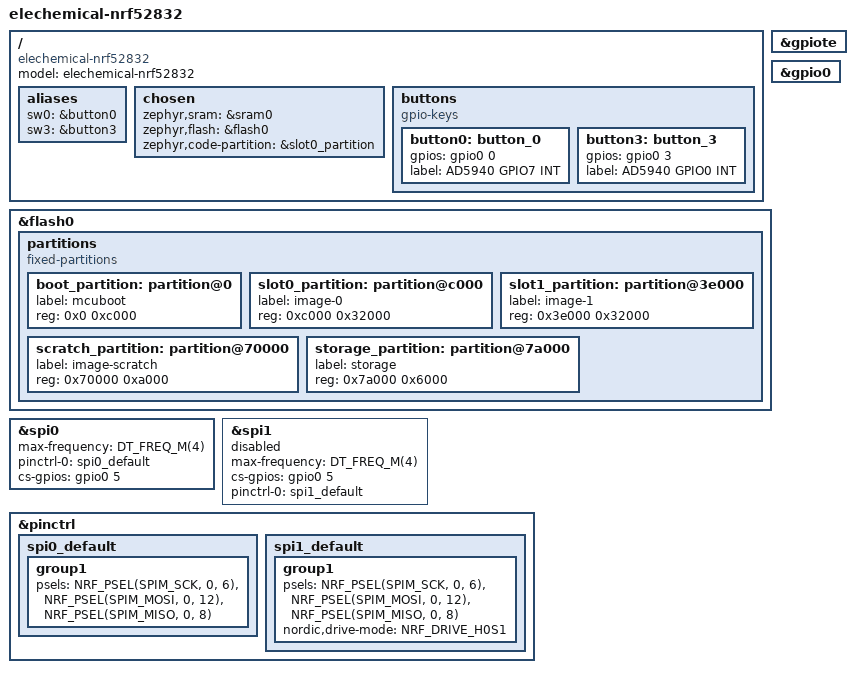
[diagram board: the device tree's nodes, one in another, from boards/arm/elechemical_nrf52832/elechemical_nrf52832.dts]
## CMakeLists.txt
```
cmake_minimum_required(VERSION 3.20.0)
find_package(Zephyr REQUIRED HINTS $ENV{ZEPHYR_BASE})

project(ElectrochemicalWorkstationNRF52832)

FILE(GLOB app_sources src/*.c include/*.h drivers/*.c drivers/*.h elec_methods/*.h elec_methods/*.c)
target_sources(app PRIVATE ${app_sources} src/main.c)
```

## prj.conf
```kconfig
CONFIG_NRFX_GPIOTE=y
CONFIG_LOG=y
CONFIG_LOG_PROCESS_THREAD_SLEEP_MS=100

# Enable RTT to replace UART
CONFIG_STDOUT_CONSOLE=y
CONFIG_UART_CONSOLE=n
CONFIG_USE_SEGGER_RTT=y
CONFIG_SHELL_BACKEND_RTT=y

# enable internal 32k rc; if u need use external XTAL, set XTAL=y, rest would be '=n' automatically.
CONFIG_CLOCK_CONTROL_NRF_K32SRC_RC=y
CONFIG_CLOCK_CONTROL_NRF_K32SRC_XTAL=n

CONFIG_NEWLIB_LIBC=y
# CONFIG_NEWLIB_LIBC_FLOAT_PRINTF=y
CONFIG_CBPRINTF_FP_SUPPORT=y

# SPIM
CONFIG_GPIO=y
CONFIG_PINCTRL=y
CONFIG_SPI=y
CONFIG_NRFX_SPI0=y

CONFIG_BT=y
CONFIG_BT_DEBUG_LOG=y
CONFIG_BT_DEVICE_NAME="ElectrochemicalWorkstation"
CONFIG_BT_PERIPHERAL=y
CONFIG_BT_BAS=y
CONFIG_BT_USER_PHY_UPDATE=y
CONFIG_BT_BUF_ACL_RX_SIZE=500
CONFIG_BT_CTLR_PHY_2M=y
#GATT_CLIENT needed for requesting ATT_MTU update
CONFIG_BT_GATT_CLIENT=y
#PHY update needed for updating PHY request
CONFIG_BT_USER_PHY_UPDATE=y
#For data length update
CONFIG_BT_USER_DATA_LEN_UPDATE=y
#This is the maximum data length with Nordic Softdevice controller
CONFIG_BT_CTLR_DATA_LENGTH_MAX=251
#These buffers are needed for the data length max. 
CONFIG_BT_BUF_ACL_TX_SIZE=500
CONFIG_BT_BUF_ACL_RX_SIZE=500
#This is the maximum MTU size with Nordic Softdevice controller
CONFIG_BT_L2CAP_TX_MTU=500

# DIS Service
CONFIG_BT_DIS=y
CONFIG_BT_DIS_PNP=n
CONFIG_BT_DIS_MODEL="ElecWs"
CONFIG_BT_DIS_MANUF="RoumaiMed"
CONFIG_BT_DIS_SERIAL_NUMBER=y
CONFIG_BT_DIS_FW_REV=y
CONFIG_BT_DIS_HW_REV=y
CONFIG_BT_DIS_SW_REV=y
CONFIG_BT_DIS_SERIAL_NUMBER_STR="F.A000001"
CONFIG_BT_DIS_FW_REV_STR="Roumai Firmware"
CONFIG_BT_DIS_HW_REV_STR="Roumai Hardware"
CONFIG_BT_DIS_SW_REV_STR="Roumai Software"
# Below is setup to let DIS information be read from settings
CONFIG_BT_SETTINGS=y
CONFIG_SETTINGS=y
CONFIG_SETTINGS_NONE=y

CONFIG_BT_DIS_SETTINGS=y
CONFIG_BT_DIS_STR_MAX=21
```

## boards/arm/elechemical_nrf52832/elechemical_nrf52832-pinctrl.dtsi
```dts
/*
 * Copyright (c) 2022 Nordic Semiconductor
 * SPDX-License-Identifier: Apache-2.0
 */

 &pinctrl {

	spi0_default: spi0_default {
		group1 {
      psels = <NRF_PSEL(SPIM_SCK, 0, 6)>,
              <NRF_PSEL(SPIM_MOSI, 0, 12)>,
              <NRF_PSEL(SPIM_MISO, 0, 8)>;
		};
	};

	spi0_sleep: spi0_sleep {
		group1 {
      psels = <NRF_PSEL(SPIM_SCK, 0, 6)>,
              <NRF_PSEL(SPIM_MOSI, 0, 12)>,
              <NRF_PSEL(SPIM_MISO, 0, 8)>;
			low-power-enable;
		};
	};

};
```

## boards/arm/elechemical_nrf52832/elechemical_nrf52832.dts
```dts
// Copyright (c) 2023 Nordic Semiconductor ASA
// SPDX-License-Identifier: Apache-2.0

/dts-v1/;
#include <nordic/nrf52832_ciaa.dtsi>
// #include "elechemical-nrf52832-pinctrl.dtsi"

/ {
	model = "elechemical-nrf52832";
	compatible = "elechemical-nrf52832";
  
  aliases {
    sw0 = &button0;
    sw3 = &button3;
  };
	
  chosen {
		zephyr,sram = &sram0;
		zephyr,flash = &flash0;
		zephyr,code-partition = &slot0_partition;
	};

  buttons {
    compatible = "gpio-keys";
    button0: button_0 {
			gpios = <&gpio0 0 (GPIO_PULL_UP | GPIO_ACTIVE_HIGH)>;
      label = "AD5940 GPIO7 INT";
    };
    button3: button_3 {
			gpios = <&gpio0 3 (GPIO_PULL_UP | GPIO_ACTIVE_HIGH)>;
      label = "AD5940 GPIO0 INT";
    };
    /* ... other buttons ... */
  };
  
};

// &uart0 {
// 	compatible = "nordic,nrf-uarte";
// 	status = "okay";
// 	current-speed = <115200>;
// 	pinctrl-0 = <&uart0_default>;
// 	pinctrl-1 = <&uart0_sleep>;
// 	pinctrl-names = "default", "sleep";
// };

&gpiote {
	status = "okay";
};

&gpio0 {
	status = "okay";
};

&flash0 {
	partitions {
		compatible = "fixed-partitions";
		#address-cells = <1>;
		#size-cells = <1>;

		boot_partition: partition@0 {
			label = "mcuboot";
			reg = <0x0 0xc000>;
		};
		slot0_partition: partition@c000 {
			label = "image-0";
			reg = <0xc000 0x32000>;
		};
		slot1_partition: partition@3e000 {
			label = "image-1";
			reg = <0x3e000 0x32000>;
		};
		scratch_partition: partition@70000 {
			label = "image-scratch";
			reg = <0x70000 0xa000>;
		};
		storage_partition: partition@7a000 {
			label = "storage";
			reg = <0x7a000 0x6000>;
		};
	};
};


&spi0 {
  status = "okay";
  max-frequency = <DT_FREQ_M(4)>;
  pinctrl-0 = <&spi0_default>;
  pinctrl-names = "default";
  cs-gpios = <&gpio0 5 0>;
};

&spi1 {
  status = "disabled";
  max-frequency = <DT_FREQ_M(4)>;
  cs-gpios = <&gpio0 5 0>;
  pinctrl-0 = <&spi1_default>;
  pinctrl-names = "default";
};

&pinctrl {
  spi0_default: spi0_default {
    group1 {
      psels = <NRF_PSEL(SPIM_SCK, 0, 6)>,
              <NRF_PSEL(SPIM_MOSI, 0, 12)>,
              <NRF_PSEL(SPIM_MISO, 0, 8)>;
    };
  };

  spi1_default: spi1_default {
    group1 {
      psels = <NRF_PSEL(SPIM_SCK, 0, 6)>,
              <NRF_PSEL(SPIM_MOSI, 0, 12)>,
              <NRF_PSEL(SPIM_MISO, 0, 8)>;
      nordic,drive-mode = <NRF_DRIVE_H0S1>;
    };
  };
};
```

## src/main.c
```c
#include <zephyr/kernel.h>
#include <zephyr/logging/log.h>
#include <zephyr/sys/util.h>
#include <zephyr/settings/settings.h>
#include <zephyr/bluetooth/bluetooth.h>
#include <zephyr/bluetooth/gatt.h>
#include <unistd.h> // For sleep function
#include <stdlib.h> // For EXIT_FAILURE and EXIT_SUCCESS

#include "../include/ble_protocal.h"
#include "../include/ble_faca.h"
#include "../drivers/ad5940_nrf52.h"
#include "../drivers/dac.h"// Include DAC driver header


LOG_MODULE_REGISTER(app, LOG_LEVEL_INF);

void mtu_updated(struct bt_conn *conn, uint16_t tx, uint16_t rx)
{
	printk("Updated MTU: TX: %d RX: %d bytes\n", tx, rx);
}

static struct bt_gatt_cb gatt_callbacks = {.att_mtu_updated = mtu_updated};

void main(void)
{
  int err = 0;
  // AD5940
  err = ad5940_spi_init();
  if (err)
  {
    LOG_ERR("AD5940 SPI init failed (err %d)", err);
    return;
  }

  err = ad5940_enable_int();
  if (err)
  {
    LOG_ERR("AD5940 INT init failed (err %d)", err);
    return;
  }
  LOG_INF("AD5940 init success.");

  // Bluetooth
  err = bt_enable(NULL);
  if (err)
  {
    LOG_ERR("Bluetooth init failed (err %d)", err);
    return;
  }
  bt_gatt_cb_register(&gatt_callbacks);
  LOG_INF("Bluetooth init success.");
  if (IS_ENABLED(CONFIG_BT_SETTINGS))
  {
    settings_load();
    LOG_INF("Settings init success.");
  }
  err = ble_init_adv();
  if (err)
  {
    LOG_ERR("Bluetooth adv init failed (err %d)", err);
    return;
  }
  LOG_INF("Bluetooth adv init success.");
  err = ble_start_adv();
  if (err)
  {
    LOG_ERR("Bluetooth adv start failed (err %d)", err);
    return;
  }
  LOG_INF("Bluetooth adv start success.");

  err = ble_faca_init();
  if (err)
  {
    LOG_ERR("Bluetooth faca init failed (err %d)", err);
    return;
  }
  LOG_INF("Bluetooth faca init success.");
  
  for(;;) {
    k_msleep(1);
  }
}

//adc
#define ADC_CHANNEL 1
void adc_task(void)
{
    if (adc_init() != 0) {
        printf("ADC初始化失败！\n");
        return;
    }
    printf("ADC初始化成功，开始读取数据...\n");

    // 循环读取ADC值
    while (1) {
        // 读取原始ADC值
        uint16_t adc_value = adc_read(ADC_CHANNEL);

        // 检查读取是否成功（假设返回0xFFFF表示失败）
        if (adc_value == 0xFFFF) {
            printf("读取ADC通道 %d 失败\n", ADC_CHANNEL);
        } else {
            // 转换为电压值
            float result = *adc_read(ADC_CHANNEL);

            // 打印结果
            printf("ADC通道 %d: 原始值 = %d, 电压 = %.2fV\n",
                   ADC_CHANNEL, adc_value, result);
        }

        // 每隔1秒读取一次
        sleep(1);
    }
    // 释放ADC资源（实际中可能不会执行到这里）
    adc_deinit();
}
```

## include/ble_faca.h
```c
#include <stdint.h>

#define BLE_CMD_BLUFI_SSIDPSWD    0x01
#define BLE_CMD_BLUFI_DISCONNECT  0x02
#define BLE_CMD_SESSION_START     0x03
#define BLE_CMD_SESSION_TS        0x04
#define BLE_CMD_SESSION_STOP      0x05
#define BLE_CMD_GET_WIFI_CONFIG   0x06
#define BLE_CMD_GET_TASK_CONFIG   0x07
#define BLE_CMD_POST_TASK_CONFIG  0x08
#define BLE_CMD_READ_REGISTER     0x09
#define BLE_CMD_WRITE_REGISTER    0x0A

int ble_faca_init();
```

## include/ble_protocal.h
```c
#include <stdint.h>

int ble_init_adv();

int ble_start_adv();

int ble_stop_adv();
```

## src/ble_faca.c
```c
#ifndef ENABLE_FACA_SERVICE__
#define ENABLE_FACA_SERVICE__

#include "../include/ble_faca.h"

#include <stdlib.h>

#include <zephyr/bluetooth/bluetooth.h>
#include <zephyr/bluetooth/hci.h>
#include <zephyr/bluetooth/conn.h>
#include <zephyr/bluetooth/uuid.h>
#include <zephyr/bluetooth/gatt.h>

#include <zephyr/logging/log.h>
LOG_MODULE_REGISTER(faca, LOG_LEVEL_INF);

// Electrochemical Methods
#include "../elec_methods/common.h"
#include "../elec_methods/ocp.h"
#include "../elec_methods/eis.h"
#include "../elec_methods/cv.h"
#include "../elec_methods/ca.h"


// Looper

#define LOOPER_INTERVAL         1     // 1ms

static void looper_work_handler(struct k_work *work);

static K_WORK_DELAYABLE_DEFINE(looper_work, looper_work_handler);

// Task
static volatile uint8_t current_elec_method = 0x00; // undefined.
static inline void reset_current_elec_method() { current_elec_method = 0x00; }

#define BLE_BUFFER_MAX_SIZE 20
static          uint8_t buffer_copi[BLE_BUFFER_MAX_SIZE];
static volatile uint8_t buffer_size = BLE_BUFFER_MAX_SIZE;
static volatile bool    buffer_done = false;

// Bluetooth

#define FACA_INDEX        0
#define FAC1_INDEX        2
#define FAC2_INDEX        4
#define FAC2_CCC_INDEX    5
#define FAC3_INDEX        7
#define FAC3_CCC_INDEX    8

static uint8_t response_values[500];
static volatile bool notify_fac2_enable;
static volatile bool notify_fac3_enable;
static void mpu_ccc_cfg_changed_fac2(const struct bt_gatt_attr *attr, uint16_t value)
{
	ARG_UNUSED(attr);
	notify_fac2_enable = (value == BT_GATT_CCC_NOTIFY);
	// LOG_INF("Notification %s", notify_enable ? "enabled" : "disabled");
}
static void mpu_ccc_cfg_changed_fac3(const struct bt_gatt_attr *attr, uint16_t value)
{
	ARG_UNUSED(attr);
	notify_fac3_enable = (value == BT_GATT_CCC_NOTIFY);
  // LOG_INF("notify_fac3_enable: %d", notify_fac3_enable ? 1 : 0);
}
static ssize_t read_faca(struct bt_conn *conn, const struct bt_gatt_attr *attr,
   void *buf, uint16_t len, uint16_t offset);
static ssize_t on_request_arrived(struct bt_conn *conn,
		    const struct bt_gatt_attr *attr, const void *buf,
		    uint16_t len, uint16_t offset, uint8_t flags);

static struct bt_uuid_128 faca_service_uuid = BT_UUID_INIT_128(
	BT_UUID_128_ENCODE(0x0000faca, 0x0000, 0x1000, 0x8000, 0x00805f9b34fb));

// FAC1: recv payload from master.
static struct bt_uuid_128 fac1_char_uuid = BT_UUID_INIT_128(
	BT_UUID_128_ENCODE(0x0000fac1, 0x0000, 0x1000, 0x8000, 0x00805f9b34fb));

// FAC2: notify normal callback.
static struct bt_uuid_128 fac2_char_uuid = BT_UUID_INIT_128(
	BT_UUID_128_ENCODE(0x0000fac2, 0x0000, 0x1000, 0x8000, 0x00805f9b34fb));

// FAC3: notify adc data. "0000fac3-0000-1000-8000-00805f9b34fb"
static struct bt_uuid_128 fac3_char_uuid = BT_UUID_INIT_128(
	BT_UUID_128_ENCODE(0x0000fac3, 0x0000, 0x1000, 0x8000, 0x00805f9b34fb));

BT_GATT_SERVICE_DEFINE(faca_service,
  BT_GATT_PRIMARY_SERVICE(&faca_service_uuid),
  BT_GATT_CHARACTERISTIC(&fac1_char_uuid.uuid,
            BT_GATT_CHRC_WRITE | BT_GATT_CHRC_WRITE_WITHOUT_RESP,
            BT_GATT_PERM_WRITE, NULL, on_request_arrived, (void *)1),
  BT_GATT_CHARACTERISTIC(&fac2_char_uuid.uuid, BT_GATT_CHRC_NOTIFY | BT_GATT_CHRC_READ,
            BT_GATT_PERM_READ | BT_GATT_PERM_WRITE, read_faca, NULL, &response_values),
  // BT_GATT_CUD("Fade2 CUD", BT_GATT_PERM_READ),
  BT_GATT_CCC(mpu_ccc_cfg_changed_fac2, BT_GATT_PERM_READ | BT_GATT_PERM_WRITE),
  BT_GATT_CHARACTERISTIC(&fac3_char_uuid.uuid, BT_GATT_CHRC_NOTIFY | BT_GATT_CHRC_READ,
            BT_GATT_PERM_READ | BT_GATT_PERM_WRITE, read_faca, NULL, &buffer_copi),
  // BT_GATT_CUD("Fade3 CUD", BT_GATT_PERM_READ),
  BT_GATT_CCC(mpu_ccc_cfg_changed_fac3, BT_GATT_PERM_READ | BT_GATT_PERM_WRITE),
);

static ssize_t read_faca(struct bt_conn *conn, const struct bt_gatt_attr *attr,
   void *buf, uint16_t len, uint16_t offset)
{
  const char *value = attr->user_data;
  return bt_gatt_attr_read(conn, attr, buf, len, offset, value, strlen(value));
}

///////////////////////////////////////////// FAC2 Reply //////////////////////////////////////////////////

// static void reply_response_with_data(uint16_t request_id, uint8_t status, uint8_t * data, uint8_t len)
// {
//   response_values[0] = (uint8_t)(request_id >> 8) & 0xFF;
//   response_values[1] = (request_id & 0xFF);
//   response_values[2] = status;
//   for (uint8_t i = 0; i < len; i++) {
//     response_values[i + 3] = data[i];
//   }
//   uint8_t err = bt_gatt_notify(NULL, &faca_service.attrs[FAC2_INDEX], &response_values, len + 3);
//   if (err) {
//     // ...
//     // LOG_ERR("faca2 reply json error, err = %02x", err);
//   }
// }
static void reply_response(uint16_t request_id, uint8_t status)
{
  response_values[0] = (uint8_t)((request_id >> 8) & 0xFF);
  response_values[1] = (request_id & 0xFF);
  response_values[2] = status;
  uint8_t err = bt_gatt_notify(NULL, &faca_service.attrs[FAC2_INDEX], &response_values, 3);
  if (err) {
    // ...
    // LOG_ERR("faca2 reply json error, err = %02x", err);
  }
}

///////////////////////////////////////////// FAC3 Notify //////////////////////////////////////////////////

// worker, implement from common.h
void send_fac_stream(uint8_t * data, uint8_t len)
{
  buffer_copi[0] = current_elec_method;
  // copy buffer
  for (uint8_t i = 0; i < len; i++) {
    buffer_copi[i + 1] = data[i];
  }
  buffer_size = len + 1;
  // signal flag
  buffer_done = true;
}

int send_fac_stream_directly(uint8_t * data, uint8_t len)
{
  uint8_t buffer_[len];
  buffer_[0] = current_elec_method;
  for (int i = 0; i < len; i++) {
    buffer_[i + 1] = data[i];
  }
  int err = bt_gatt_notify(NULL, &faca_service.attrs[FAC3_INDEX], &buffer_, (len + 1));
  if (err) {
    return err;
  }
  return 0;
}


#define COMMIT_BUFFER_MAX_LEN 4096
#define COMMIT_BUFFER_EACH_LEN 20
static volatile uint32_t c_buffer_size;
static volatile uint32_t c_buffer_index; // for sender process.
static uint8_t c_buffer[COMMIT_BUFFER_MAX_LEN];
void commit_fac_stream(uint8_t * data, uint8_t len, bool append)
{
  // buffer here.
  int index = 0;
  if (append) {
    index = c_buffer_size;
  } else {
    index = 0;
    c_buffer_index = 0;
  }
  for(int i = 0; i < len; i++) {
    c_buffer[index++] = data[i];
  }
  c_buffer_size = index;
}


static inline void stop_other_elec_methods(uint8_t except_code) {
  if (except_code != CODE_OCP) {
    if (elec_ocp_is_working()) elec_ocp_stop();
  }
  if (except_code != CODE_EIS) {
    if (elec_eis_is_working()) elec_eis_stop();
  }
  if (except_code != CODE_CV) {
    if (elec_cv_is_working()) elec_cv_stop();
  }
  k_msleep(500); // 延迟 500ms 确保 AD5940 能正确重置
  // reset ad5940
  // ...
}


static ssize_t on_request_arrived(struct bt_conn *conn,
		    const struct bt_gatt_attr *attr, const void *buf,
		    uint16_t len, uint16_t offset, uint8_t flags)
{
  // parse json.
  LOG_INF("payload len: %d", len);
  if (len == 1) { // debug mode
    int err = 0; // ad594x_verify();
    LOG_INF("faca: ad594x debug verify: %02x", err);
    return 0;
  }
  /**
   * 
   * Request Payload Parser & Resp.
   * 
  */
  uint8_t * data = (uint8_t *)buf;
  uint16_t request_id = (uint16_t)(data[0] << 8) | (data[1] & 0xFF);
  uint8_t method = data[2] & 0xFF;
  switch(method) {
  case 0x01: // 计时电流法
  {
    break;
  }
  case CODE_OCP: // OCP
  {
    uint8_t code = data[3];
    if (code == 0x01) { // start cmd
      LOG_INF("Router: OCP/start");
      if (elec_ocp_is_working()) {
        reply_response(request_id, 1);
      } else {
        stop_other_elec_methods(method);
        elec_ocp_init();
        reply_response(request_id, 0);
        current_elec_method = method;
        // start work
        elec_ocp_start();
        // elec_ocp_start(&send_fac_stream);
      }
      break;
    }
    if (code == 0x02) { // stop cmd
      LOG_INF("Router: OCP/stop");
      elec_ocp_stop();
      reply_response(request_id, 0);
      reset_current_elec_method(); // reset
      break;
    }
    if (code == 0x03) { // config
      LOG_INF("Router: OCP/config");
      opc_config_t config;
      config.sample_frequency = data[4]; // positive integer, range in 1..50
      if (len >= 7) {
        config.delay = (data[5] << 8) | data[6];
      }
      elec_ocp_config(config);
      reply_response(request_id, 0);
      break;
    }
    break;
  }
  case CODE_EIS: // EIS
  {
    uint8_t code = data[3];
    if (code == 0x01) { // start cmd
      LOG_INF("Router: EIS/start");
      if (elec_eis_is_working()) {
        reply_response(request_id, 1);
      } else {
        stop_other_elec_methods(method);
        reply_response(request_id, 0);
        LOG_INF("EIS init#begin");
        elec_eis_init(); // will take a lot of time.
        current_elec_method = method;
        // start work
        LOG_INF("EIS start#begin");
        elec_eis_start();
        LOG_INF("EIS start#end");
      }
      break;
    }
    if (code == 0x02) { // stop cmd
      LOG_INF("Router: EIS/stop");
      elec_eis_stop();
      reply_response(request_id, 0);
      reset_current_elec_method(); // reset
      break;
    }
    if (code == 0x03) { // config cmd
      LOG_INF("Router: EIS/config");
      if (len < 19) {
        reply_response(request_id, 1);
        break;
      }
      uint32_t freq_begin = ((uint32_t)data[4]) << 24;
      freq_begin |= ((uint32_t)data[5]) << 16;
      freq_begin |= ((uint32_t)data[6]) << 8;
      freq_begin |= data[7] & 0xFF;

      uint32_t freq_end = ((uint32_t)data[8]) << 24;
      freq_end |= ((uint32_t)data[9]) << 16;
      freq_end |= ((uint32_t)data[10]) << 8;
      freq_end |= data[11] & 0xFF;

      uint16_t sample_count = ((uint32_t)data[12]) << 8;
      sample_count |= data[13] & 0xFF;

      bool use_log = data[14] > 0;

      int16_t ac_volt = ((uint32_t)data[15]) << 24;
      ac_volt |= ((uint32_t)data[16]) << 16;
      ac_volt |= ((uint32_t)data[17]) << 8;
      ac_volt |= data[18] & 0xFF;

      elec_eis_config_t config;
      config.freq_begin = freq_begin / 100.0F;
      config.freq_end   = freq_end / 100.0F;
      config.sample_count = sample_count;
      config.use_log    = use_log;
      config.ac_volt    = ac_volt / 100.0F;

      LOG_INF("=======eis config updated========");
      LOG_INF("freq begin:    %f Hz", config.freq_begin);
      LOG_INF("freq end:      %f Hz", config.freq_end);
      LOG_INF("sample count:  %d", config.sample_count);
      LOG_INF("use_log:       %s", config.use_log ? "yes" : "no");
      LOG_INF("ac volt:       %f mV", config.ac_volt);
      LOG_INF("=======eis config updated========");

      elec_eis_config(config);
      reply_response(request_id, 0);
      break;
    }
    break;
  }
  case CODE_CV: // CV
  {
    uint8_t code = data[3];
    if (code == 0x01) { // start cmd
      LOG_INF("Router: CV/start");
      if (elec_cv_is_working()) {
        reply_response(request_id, 1);
      } else {
        stop_other_elec_methods(method);
        elec_cv_init();
        reply_response(request_id, 0);
        current_elec_method = method;
        // start work
        elec_cv_start();
      }
      break;
    }
    if (code == 0x02) { // stop cmd
      LOG_INF("Router: CV/stop");
      elec_cv_stop();
      reply_response(request_id, 0);
      reset_current_elec_method(); // reset
      break;
    }
    if (code == 0x03) { // config cmd
      LOG_INF("Router: CV/config");
      if (len < 26) { // valid len: 6*int + 1*short = 26
        reply_response(request_id, 1);
        break;
      }
      int k = 4;
      elec_cv_config_t config;

      uint8_t rtia = data[k++];
      if (rtia > 0 && rtia <= 26) {
        config.rtia = rtia;
      }

      int32_t vertex_begin = ((uint32_t)data[k++]) << 24;
      vertex_begin |= ((uint32_t)data[k++]) << 16;
      vertex_begin |= ((uint32_t)data[k++]) << 8;
      vertex_begin |= data[k++] & 0xFF;
      config.vertex_begin = vertex_begin / 100.0f; // mV

      int32_t vertex_1 = ((uint32_t)data[k++]) << 24;
      vertex_1 |= ((uint32_t)data[k++]) << 16;
      vertex_1 |= ((uint32_t)data[k++]) << 8;
      vertex_1 |= data[k++] & 0xFF;
      config.vertex_1 = vertex_1 / 100.0f; // mV

      int32_t vertex_2 = ((uint32_t)data[k++]) << 24;
      vertex_2 |= ((uint32_t)data[k++]) << 16;
      vertex_2 |= ((uint32_t)data[k++]) << 8;
      vertex_2 |= data[k++] & 0xFF;
      config.vertex_2 = vertex_2 / 100.0f; // mV

      int32_t sample_delay = ((uint32_t)data[k++]) << 24;
      sample_delay |= ((uint32_t)data[k++]) << 16;
      sample_delay |= ((uint32_t)data[k++]) << 8;
      sample_delay |= data[k++] & 0xFF;
      config.sample_delay = sample_delay / 100.0f; // ms

      int32_t scan_rate = ((uint32_t)data[k++]) << 24;
      scan_rate |= ((uint32_t)data[k++]) << 16;
      scan_rate |= ((uint32_t)data[k++]) << 8;
      scan_rate |= data[k++] & 0xFF;
      config.scan_rate = scan_rate / 100.0f; // mV/s

      int32_t step_value = ((uint32_t)data[k++]) << 24;
      step_value |= ((uint32_t)data[k++]) << 16;
      step_value |= ((uint32_t)data[k++]) << 8;
      step_value |= data[k++] & 0xFF;
      config.step_value = step_value / 100.0f; // mV

      uint16_t cycle_number = ((uint16_t)data[k++]) << 8;
      cycle_number |= data[k++] & 0xFF;
      config.cycle_number = cycle_number;

      LOG_INF("=======cv config updated========");
      LOG_INF("begin volt:       %f mV", config.vertex_begin);
      LOG_INF("vertex1 volt:     %f mV", config.vertex_1);
      LOG_INF("vertex2 start:    %f mV", config.vertex_2);
      LOG_INF("step:             %f mV", config.step_value);
      LOG_INF("scan rate:        %f mV/s", config.scan_rate);
      LOG_INF("sample delay:     %f ms", config.sample_delay);
      LOG_INF("cycle number:     %d",    config.cycle_number);
      LOG_INF("r tia:            %d",    config.rtia);
      LOG_INF("=======cv config updated========");
      elec_cv_config(config);

      reply_response(request_id, 0);
      break;
    }
    break;
  }
  case CODE_CA: // CA
  {
    uint8_t code = data[3];
    if (code == 0x01) { // start cmd
      LOG_INF("Router: CA/start");
      if (elec_ca_is_working()) {
        reply_response(request_id, 1);
      } else {
        stop_other_elec_methods(method);
        elec_ca_init();
        reply_response(request_id, 0);
        current_elec_method = method;
        // start work
        elec_ca_start();
      }
      break;
    }
    if (code == 0x02) { // stop cmd
      LOG_INF("Router: CA/stop");
      elec_ca_stop();
      reply_response(request_id, 0);
      reset_current_elec_method(); // reset
      break;
    }
    if (code == 0x03) { // config cmd
      LOG_INF("Router: CA/config");
      if (len < 12) { // valid len: 10
        reply_response(request_id, 1);
        break;
      }
      int k = 4;
      elec_ca_config_t config;
      int32_t amp = ((uint32_t)data[k++]) << 24;
      amp |= ((uint32_t)data[k++]) << 16;
      amp |= ((uint32_t)data[k++]) << 8;
      amp |= data[k++] & 0xFF;

      uint16_t ms = ((uint16_t)data[k++]) << 24;
      ms |= ((uint32_t)data[k++]) << 16;
      ms |= ((uint32_t)data[k++]) << 8;
      ms |= data[k++] & 0xFF;

      config.amplitude  = amp / 100.0f;  // mV
      config.ms    = ms;   // ms

      LOG_INF("=======ca config updated========");
      LOG_INF("start volt:    %f mV", config.amplitude);
      LOG_INF("peak volt:     %d ms", config.ms);
      LOG_INF("=======ca config updated========");
      elec_ca_config(config);

      reply_response(request_id, 0);
      break;
    }
    break;
  }
  default: break;
  }
	return 0;
}


static void looper_work_handler(struct k_work *work)
{
  // if (!notify_fac3_enable) return;
  if (buffer_done) 
  {
    buffer_done = false;
    // notify
    uint8_t err = bt_gatt_notify(NULL, &faca_service.attrs[FAC3_INDEX], &buffer_copi, buffer_size);
    if (err) {
      // ...
      // retry--
      err = bt_gatt_notify(NULL, &faca_service.attrs[FAC3_INDEX], &buffer_copi, buffer_size);
    }
  }
  int max_len = c_buffer_size - c_buffer_index;
  if (max_len > 1) {
    int len = max_len > COMMIT_BUFFER_EACH_LEN ? COMMIT_BUFFER_EACH_LEN : max_len;
    uint8_t buffer_c_copi[len];
    for (int i = 0; i < len; i++) {
      buffer_c_copi[i] = c_buffer[c_buffer_index + i];
    }
    int err = bt_gatt_notify(NULL, &faca_service.attrs[FAC3_INDEX], &buffer_c_copi, len);
    if (err) {
      // retry
    } else {
      c_buffer_index += len;
    }
  }
	k_work_reschedule(k_work_delayable_from_work(work), K_MSEC(LOOPER_INTERVAL));
}

int ble_faca_init()
{
  int err = 0;
  err = k_work_schedule(&looper_work, K_NO_WAIT);
  return 0;
}

#endif
```

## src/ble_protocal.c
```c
#include "../include/ble_protocal.h"

#include <zephyr/kernel.h>
#include <zephyr/bluetooth/bluetooth.h>
#include <zephyr/bluetooth/hci.h>
#include <zephyr/bluetooth/conn.h>
#include <zephyr/bluetooth/gatt.h>
#include <zephyr/bluetooth/uuid.h>

#include <zephyr/logging/log.h>
LOG_MODULE_REGISTER(blec, LOG_LEVEL_INF);

#define DEVICE_NAME CONFIG_BT_DEVICE_NAME
#define DEVICE_NAME_LEN (sizeof(DEVICE_NAME) - 1)
static volatile bool device_connected = false;
static void start_advertising();

static const struct bt_data ad[] = {
  // BT_DATA_BYTES(BT_DATA_FLAGS, BT_LE_AD_NO_BREDR),
  // BT_DATA_BYTES(BT_DATA_UUID16_ALL, 0xde, 0xfa), // X16-Service
  // BT_DATA_BYTES(BT_DATA_SVC_DATA16, 0xde, 0xfa, 'n', 'o', 'r', 'd', 'i', 'c') // nordic version.
  
	BT_DATA_BYTES(BT_DATA_FLAGS, (BT_LE_AD_GENERAL | BT_LE_AD_NO_BREDR)),
	BT_DATA_BYTES(BT_DATA_UUID16_ALL,
            BT_UUID_16_ENCODE(0xfaca),  // FACA
					  BT_UUID_16_ENCODE(BT_UUID_BAS_VAL),  // BAT
					  BT_UUID_16_ENCODE(BT_UUID_DIS_VAL)), // DIS
	// BT_DATA(BT_DATA_NAME_COMPLETE, DEVICE_NAME, DEVICE_NAME_LEN)
};

// Set Scan Response data
static const struct bt_data sd[] = {
    BT_DATA(BT_DATA_NAME_COMPLETE, DEVICE_NAME, DEVICE_NAME_LEN),
};

static void connected(struct bt_conn *conn, uint8_t conn_err)
{
	int err;
	struct bt_conn_info info;
	char addr[BT_ADDR_LE_STR_LEN];

	bt_addr_le_to_str(bt_conn_get_dst(conn), addr, sizeof(addr));

	if (conn_err) {
		LOG_INF("Connection failed (err %d)\n", conn_err);
		return;
	}
  if (!device_connected) {
		device_connected = true;
    // device_connected = (NULL != bt_conn_ref(conn));
    // stop adv
    ble_stop_adv();
  }
  // dis service
	err = bt_conn_get_info(conn, &info);
	if (err) {
		LOG_INF("Failed to get connection info (err %d)\n", err);
	} else {
		const struct bt_conn_le_phy_info *phy_info;
		phy_info = info.le.phy;

		LOG_INF("Connected: %s, tx_phy %u, rx_phy %u\n",
		       addr, phy_info->tx_phy, phy_info->rx_phy);
	}
}

static void disconnected(struct bt_conn *conn, uint8_t err)
{
	LOG_INF("Disconnected (reason 0x%02x)\n", err);
  if (err) {
  } else {
  }
  if (device_connected) {
		device_connected = false;
    // bt_conn_unref(conn);
    // start adv again.
    ble_start_adv();
  }
}

// define callback
BT_CONN_CB_DEFINE(conn_callbacks) = {
	.connected = connected,
	.disconnected = disconnected,
};

static void start_advertising()
{
	int err;
	err = bt_le_adv_start(BT_LE_ADV_CONN_NAME, ad, ARRAY_SIZE(ad), NULL, 0);
	if (err) {
		LOG_INF("Failed to start advertising set (err %d)\n", err);
		return;
	}
	LOG_INF("Advertiser started\n");
}

int ble_start_adv()
{	
  start_advertising();
  return 0;
}

int ble_stop_adv()
{
  return bt_le_adv_stop();
}

int ble_init_adv()
{
  int err = 0;
  return err;
}
```
